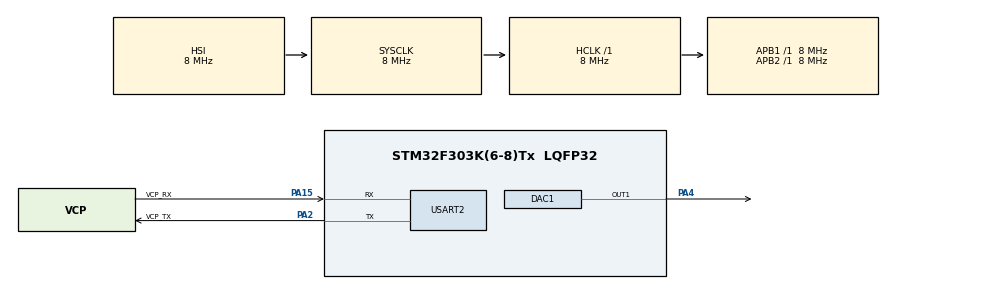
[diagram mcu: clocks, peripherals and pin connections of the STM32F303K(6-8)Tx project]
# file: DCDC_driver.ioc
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Mcu.Family=STM32F3
Mcu.Name=STM32F303K(6-8)Tx
Mcu.Package=LQFP32
NVIC.PriorityGroup=NVIC_PRIORITYGROUP_4
PA13.GPIO_Label=SWDIO
PA13.Mode=Serial_Wire
PA13.Signal=SYS_JTMS-SWDIO
PA14.GPIO_Label=SWCLK
PA14.Mode=Serial_Wire
PA14.Signal=SYS_JTCK-SWCLK
PA15.GPIO_Label=VCP_RX
PA15.Mode=Asynchronous
PA15.Signal=USART2_RX
PA2.GPIO_Label=VCP_TX
PA2.Mode=Asynchronous
PA2.Signal=USART2_TX
PA4.Signal=COMP_DAC11_group
PF0\ /\ OSC_IN.GPIO_Label=MCO
PF0\ /\ OSC_IN.Mode=HSE-External-Clock-Source
PF0\ /\ OSC_IN.Signal=RCC_OSC_IN
ProjectManager.HeapSize=0x200
ProjectManager.StackSize=0x400
ProjectManager.TargetToolchain=STM32CubeIDE
RCC.AHBFreq_Value=8000000
RCC.APB1Freq_Value=8000000
RCC.APB2Freq_Value=8000000
RCC.CortexFreq_Value=8000000
RCC.HSE_VALUE=8000000
RCC.HSI_VALUE=8000000
RCC.SYSCLKFreq_VALUE=8000000
SH.COMP_DAC11_group.0=DAC1_OUT1,DAC_OUT1
USART2.VirtualMode-Asynchronous=VM_ASYNC
board=NUCLEO-F303K8

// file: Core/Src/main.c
/* USER CODE BEGIN Header */
/**
  ******************************************************************************
  * @file           : main.c
  * @brief          : Main program body
  ******************************************************************************
  * @attention
  *
  * Copyright (c) 2026 STMicroelectronics.
  * All rights reserved.
  *
  * This software is licensed under terms that can be found in the LICENSE file
  * in the root directory of this software component.
  * If no LICENSE file comes with this software, it is provided AS-IS.
  *
  ******************************************************************************
  */
/* USER CODE END Header */
#include "main.h"

DAC_HandleTypeDef hdac1;

UART_HandleTypeDef huart2;

void SystemClock_Config(void);
static void MX_GPIO_Init(void);
static void MX_DAC1_Init(void);
static void MX_USART2_UART_Init(void);

/* USER CODE BEGIN 0 */

void Set_CC_Limit(float target_amps) {
    // 1. Zabezpieczenie (zakres realny dla tych rezystorów to teraz około 8A)
    if (target_amps > 8.0f) {
        target_amps = 8.0f;
    }
    if (target_amps <= 0.0f) {
        // Twarde wyłączenie dla zera (pokonanie offsetu)
        HAL_DAC_SetValue(&hdac1, DAC_CHANNEL_1, DAC_ALIGN_12B_R, 0);
        return;
    }

    // 2. Korekta na podstawie Twoich pomiarów (Kalibracja)
    // Aby uzyskać realne 2.0A, funkcja musi wymusić "starą" nastawę ok 1.66f
    float corrected_amps = (target_amps + 1.0f) / 1.8f;

    // 3. Stara matematyka przeliczająca skorygowaną wartość na DAC
    uint32_t dac_value = (uint32_t)((corrected_amps * 0.505f / 3.3f) * 4095.0f);

    // Zabezpieczenie DAC przed przepełnieniem
    if (dac_value > 4095) dac_value = 4095;

    // 4. Wysłanie do układu
    HAL_DAC_SetValue(&hdac1, DAC_CHANNEL_1, DAC_ALIGN_12B_R, dac_value);
}

/* USER CODE END 0 */

int main(void)
{

  /* MCU Configuration--------------------------------------------------------*/

  /* Reset of all peripherals, Initializes the Flash interface and the Systick. */
  HAL_Init();

  /* Configure the system clock */
  SystemClock_Config();

  /* Initialize all configured peripherals */
  MX_GPIO_Init();
  MX_DAC1_Init();
  MX_USART2_UART_Init();
  /* USER CODE BEGIN 2 */

  // Uruchomienie peryferium DAC
    HAL_DAC_Start(&hdac1, DAC_CHANNEL_1);

    // Ustawienie początkowe na 0 Amperów dla bezpieczeństwa!

   Set_CC_Limit(0.0f);

  /* USER CODE END 2 */

  /* Infinite loop */
  /* USER CODE BEGIN WHILE */
  while (1)
  {
	  // Test: Ustaw 1.0 A, poczekaj 5 sekund
	  // Wyjście A3 na devboardzie brązowy i GND niebieski
	        Set_CC_Limit(2.0f);
	        HAL_Delay(3000);

	        /*Set_CC_Limit(0.1f);
	       	HAL_Delay(3000);

	        Set_CC_Limit(0.2f);
	       	HAL_Delay(3000);

	        Set_CC_Limit(0.3f);
	        HAL_Delay(3000);

	        Set_CC_Limit(0.4f);
	       	HAL_Delay(3000);

	        Set_CC_Limit(0.5f);
	       	HAL_Delay(3000);

	        Set_CC_Limit(0.6f);
	        HAL_Delay(3000);

	        Set_CC_Limit(0.7f);
	       	HAL_Delay(3000);

	        Set_CC_Limit(2.8f);
	       	HAL_Delay(3000);*/

    /* USER CODE END WHILE */

  }
}

void SystemClock_Config(void)
{
  RCC_OscInitTypeDef RCC_OscInitStruct = {0};
  RCC_ClkInitTypeDef RCC_ClkInitStruct = {0};

  /** Initializes the RCC Oscillators according to the specified parameters
  * in the RCC_OscInitTypeDef structure.
  */
  RCC_OscInitStruct.OscillatorType = RCC_OSCILLATORTYPE_HSI;
  RCC_OscInitStruct.HSIState = RCC_HSI_ON;
  RCC_OscInitStruct.HSICalibrationValue = RCC_HSICALIBRATION_DEFAULT;
  RCC_OscInitStruct.PLL.PLLState = RCC_PLL_NONE;
  if (HAL_RCC_OscConfig(&RCC_OscInitStruct) != HAL_OK)
  {
    Error_Handler();
  }

  /** Initializes the CPU, AHB and APB buses clocks
  */
  RCC_ClkInitStruct.ClockType = RCC_CLOCKTYPE_HCLK|RCC_CLOCKTYPE_SYSCLK
                              |RCC_CLOCKTYPE_PCLK1|RCC_CLOCKTYPE_PCLK2;
  RCC_ClkInitStruct.SYSCLKSource = RCC_SYSCLKSOURCE_HSI;
  RCC_ClkInitStruct.AHBCLKDivider = RCC_SYSCLK_DIV1;
  RCC_ClkInitStruct.APB1CLKDivider = RCC_HCLK_DIV1;
  RCC_ClkInitStruct.APB2CLKDivider = RCC_HCLK_DIV1;

  if (HAL_RCC_ClockConfig(&RCC_ClkInitStruct, FLASH_LATENCY_0) != HAL_OK)
  {
    Error_Handler();
  }
}

static void MX_DAC1_Init(void)
{

  DAC_ChannelConfTypeDef sConfig = {0};

  /** DAC Initialization
  */
  hdac1.Instance = DAC1;
  if (HAL_DAC_Init(&hdac1) != HAL_OK)
  {
    Error_Handler();
  }

  /** DAC channel OUT1 config
  */
  sConfig.DAC_Trigger = DAC_TRIGGER_NONE;
  sConfig.DAC_OutputBuffer = DAC_OUTPUTBUFFER_ENABLE;
  if (HAL_DAC_ConfigChannel(&hdac1, &sConfig, DAC_CHANNEL_1) != HAL_OK)
  {
    Error_Handler();
  }

}

static void MX_USART2_UART_Init(void)
{

  huart2.Instance = USART2;
  huart2.Init.BaudRate = 38400;
  huart2.Init.WordLength = UART_WORDLENGTH_8B;
  huart2.Init.StopBits = UART_STOPBITS_1;
  huart2.Init.Parity = UART_PARITY_NONE;
  huart2.Init.Mode = UART_MODE_TX_RX;
  huart2.Init.HwFlowCtl = UART_HWCONTROL_NONE;
  huart2.Init.OverSampling = UART_OVERSAMPLING_16;
  huart2.Init.OneBitSampling = UART_ONE_BIT_SAMPLE_DISABLE;
  huart2.AdvancedInit.AdvFeatureInit = UART_ADVFEATURE_NO_INIT;
  if (HAL_UART_Init(&huart2) != HAL_OK)
  {
    Error_Handler();
  }

}

static void MX_GPIO_Init(void)
{

  /* GPIO Ports Clock Enable */
  __HAL_RCC_GPIOF_CLK_ENABLE();
  __HAL_RCC_GPIOA_CLK_ENABLE();

}

void Error_Handler(void)
{
  __disable_irq();
  while (1)
  {
  }
}
